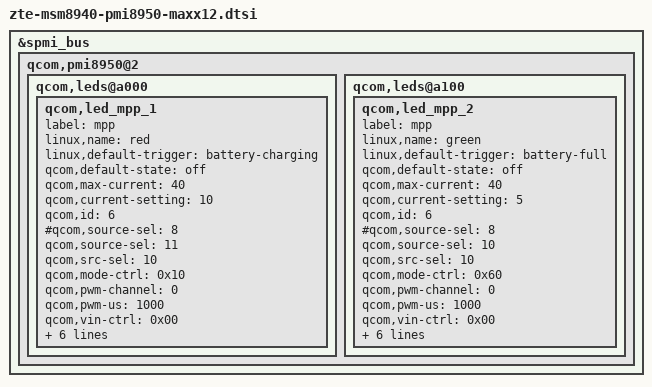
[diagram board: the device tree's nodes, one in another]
/*
 * Copyright (c) 2016, The Linux Foundation. All rights reserved.
 *
 * This program is free software; you can redistribute it and/or modify
 * it under the terms of the GNU General Public License version 2 and
 * only version 2 as published by the Free Software Foundation.
 *
 * This program is distributed in the hope that it will be useful,
 * but WITHOUT ANY WARRANTY; without even the implied warranty of
 * MERCHANTABILITY or FITNESS FOR A PARTICULAR PURPOSE.  See the
 * GNU General Public License for more details.
 */

&spmi_bus {

	qcom,pmi8950@2 {
		qcom,leds@a000 {
			status = "okay";
			qcom,led_mpp_1 {	/* red led */
				label = "mpp";
				linux,name = "red";
				linux,default-trigger = "battery-charging";
				qcom,default-state = "off";
				qcom,max-current = <40>;
				qcom,current-setting = <10>;
				qcom,id = <6>;
				#qcom,source-sel = <8>;
				qcom,source-sel = <11>; /* connect MPP to inverted DTEST2*/
				qcom,src-sel = <10>;

				qcom,mode-ctrl = <0x10>;
				qcom,pwm-channel = <0>;
				qcom,pwm-us = <1000>;
				qcom,vin-ctrl = <0x00>;
				qcom,duty-pcts = <50>;
				qcom,mode = "pwm";
				qcom,use-blink;
				pwms = <&pmi8950_pwm 0 0>;
				qcom,pwm-names = "red-led";
				zfg,is-operator-sprint = "no";
			};
		};

		qcom,leds@a100 {
			status = "okay";
			qcom,led_mpp_2 {	/* green led */
				label = "mpp";
				linux,name = "green";		/* orgin is wled-backlight */
				linux,default-trigger = "battery-full";	/* org="bkl-trigger"; */
				qcom,default-state = "off";
				qcom,max-current = <40>;
				qcom,current-setting = <5>;	
				qcom,id = <6>;				/* in leds-qpnp.c enum QPNP_ID_LED_MPP(6) */
				#qcom,source-sel = <8>;		/* select power source, default 1 (enabled)(org=8) */
				qcom,source-sel = <10>; /* connect MPP to DTEST2*/
				qcom,src-sel = <10>;
				qcom,mode-ctrl = <0x60>;	/* operation mode, default 0x60 = Mode Sink (org=0x10)*/
				qcom,pwm-channel = <0>;
				qcom,pwm-us = <1000>;
				qcom,vin-ctrl = <0x00>;		/* select input source, 0 to 3 */
				qcom,duty-pcts = <50>;
				qcom,mode = "pwm";
				qcom,use-blink;
				pwms = <&pmi8950_pwm 0 0>;
				qcom,pwm-names = "green-led";
				zfg,is-operator-sprint = "no";
			};
		};
	};
};
